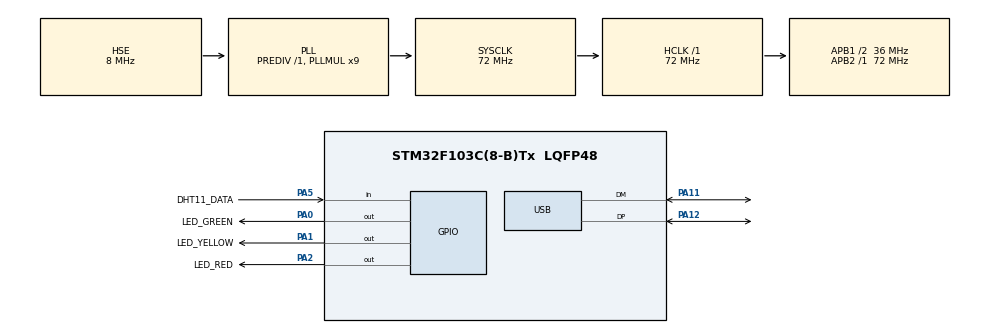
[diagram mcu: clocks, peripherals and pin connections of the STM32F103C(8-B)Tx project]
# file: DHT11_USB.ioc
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Mcu.Family=STM32F1
Mcu.Name=STM32F103C(8-B)Tx
Mcu.Package=LQFP48
NVIC.PriorityGroup=NVIC_PRIORITYGROUP_4
NVIC.USB_HP_CAN1_TX_IRQn=true\:0\:0\:false\:false\:true\:true\:true\:true
NVIC.USB_LP_CAN1_RX0_IRQn=true\:0\:0\:false\:false\:true\:false\:true\:true
PA0-WKUP.GPIO_Label=LED_GREEN
PA0-WKUP.Signal=GPIO_Output
PA1.GPIO_Label=LED_YELLOW
PA1.Signal=GPIO_Output
PA11.Mode=Device
PA11.Signal=USB_DM
PA12.Mode=Device
PA12.Signal=USB_DP
PA13.Mode=Serial_Wire
PA13.Signal=SYS_JTMS-SWDIO
PA14.Mode=Serial_Wire
PA14.Signal=SYS_JTCK-SWCLK
PA2.GPIO_Label=LED_RED
PA2.Signal=GPIO_Output
PA5.GPIO_Label=DHT11_DATA
PA5.Signal=GPIO_Input
PD0-OSC_IN.Mode=HSE-External-Oscillator
PD0-OSC_IN.Signal=RCC_OSC_IN
PD1-OSC_OUT.Mode=HSE-External-Oscillator
PD1-OSC_OUT.Signal=RCC_OSC_OUT
ProjectManager.HeapSize=0x200
ProjectManager.StackSize=0x400
ProjectManager.TargetToolchain=MDK-ARM V5.32
RCC.AHBFreq_Value=72000000
RCC.APB1CLKDivider=RCC_HCLK_DIV2
RCC.APB1Freq_Value=36000000
RCC.APB1TimFreq_Value=72000000
RCC.APB2Freq_Value=72000000
RCC.APB2TimFreq_Value=72000000
RCC.HCLKFreq_Value=72000000
RCC.PLLMUL=RCC_PLL_MUL9
RCC.SYSCLKFreq_VALUE=72000000
RCC.SYSCLKSource=RCC_SYSCLKSOURCE_PLLCLK
RCC.USBFreq_Value=48000000
RCC.USBPrescaler=RCC_USBCLKSOURCE_PLL_DIV1_5
TIM1.Prescaler=72-1
USB_DEVICE.CLASS_NAME_FS=CDC
USB_DEVICE.VirtualMode=Cdc
USB_DEVICE.VirtualModeFS=Cdc_FS
VP_TIM1_VS_ClockSourceINT.Mode=Internal
VP_USB_DEVICE_VS_USB_DEVICE_CDC_FS.Mode=CDC_FS
board=custom

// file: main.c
/* USER CODE BEGIN Header */
/**
  ******************************************************************************
  * @file           : main.c
  * @brief          : Main program body - DHT11 + USB CDC + LED control (AUTO/MANUAL)
  ******************************************************************************
  */
/* USER CODE END Header */

#include "main.h"
#include "tim.h"
#include "usb_device.h"
#include "gpio.h"

/* USER CODE BEGIN Includes */
#include "DHT11.h"
#include "usbd_cdc_if.h"
#include "mode.h"

#include <string.h>
#include <stdio.h>
/* USER CODE END Includes */

/* USER CODE BEGIN PV */
uint8_t temp = 0, humi = 0;
char msg[128];
uint32_t lastTick = 0;   // m?c th?i gian cho AUTO mode
/* USER CODE END PV */

void SystemClock_Config(void);
/* USER CODE BEGIN PFP */
void CDC_Send_String(char *s);
/* USER CODE END PFP */

/* USER CODE BEGIN 0 */
void CDC_Send_String(char *s)
{
  uint16_t len = (uint16_t)strlen(s);
  if (len == 0) return;

  while (CDC_Transmit_FS((uint8_t*)s, len) == USBD_BUSY)
  {
    HAL_Delay(1);
  }
}
/* USER CODE END 0 */

int main(void)
{
  HAL_Init();
  SystemClock_Config();

  MX_GPIO_Init();
  MX_TIM1_Init();
  MX_USB_DEVICE_Init();

  HAL_TIM_Base_Start(&htim1);

  CDC_Send_String("STM32 DHT11 USB CDC ready\r\n");

  while (1)
  {
    if (mode == MODE_AUTO)
    {
      if (HAL_GetTick() - lastTick >= 10000)
      {
        lastTick = HAL_GetTick();

        uint8_t success = 0;
        for (int i = 0; i < 3; ++i)
        {
          if (DHT11_Read(&temp, &humi) == 0)
          {
            success = 1;
            break;
          }
          HAL_Delay(100);
        }

        if (success)
        {
          HAL_GPIO_WritePin(GPIOA, GPIO_PIN_0, (humi < 40) ? GPIO_PIN_SET : GPIO_PIN_RESET);
          HAL_GPIO_WritePin(GPIOA, GPIO_PIN_1, (humi >= 40 && humi <= 70) ? GPIO_PIN_SET : GPIO_PIN_RESET);
          HAL_GPIO_WritePin(GPIOA, GPIO_PIN_2, (humi > 70) ? GPIO_PIN_SET : GPIO_PIN_RESET);

          snprintf(msg, sizeof(msg), "Temp: %d C, Humi: %d %%\r\n", temp, humi);
          CDC_Send_String(msg);
        }
        else
        {
          HAL_GPIO_WritePin(GPIOA, GPIO_PIN_0|GPIO_PIN_1|GPIO_PIN_2, GPIO_PIN_SET);
          CDC_Send_String("DHT11 Error\r\n");
        }
      }
    }
    else // MODE_MANUAL
    {
      HAL_Delay(50);
    }
  }
}

void SystemClock_Config(void)
{
  RCC_OscInitTypeDef RCC_OscInitStruct = {0};
  RCC_ClkInitTypeDef RCC_ClkInitStruct = {0};
  RCC_PeriphCLKInitTypeDef PeriphClkInit = {0};

  RCC_OscInitStruct.OscillatorType = RCC_OSCILLATORTYPE_HSE;
  RCC_OscInitStruct.HSEState = RCC_HSE_ON;
  RCC_OscInitStruct.HSEPredivValue = RCC_HSE_PREDIV_DIV1;
  RCC_OscInitStruct.HSIState = RCC_HSI_ON;
  RCC_OscInitStruct.PLL.PLLState = RCC_PLL_ON;
  RCC_OscInitStruct.PLL.PLLSource = RCC_PLLSOURCE_HSE;
  RCC_OscInitStruct.PLL.PLLMUL = RCC_PLL_MUL9;
  if (HAL_RCC_OscConfig(&RCC_OscInitStruct) != HAL_OK) Error_Handler();

  RCC_ClkInitStruct.ClockType = RCC_CLOCKTYPE_HCLK|RCC_CLOCKTYPE_SYSCLK
                              |RCC_CLOCKTYPE_PCLK1|RCC_CLOCKTYPE_PCLK2;
  RCC_ClkInitStruct.SYSCLKSource = RCC_SYSCLKSOURCE_PLLCLK;
  RCC_ClkInitStruct.AHBCLKDivider = RCC_SYSCLK_DIV1;
  RCC_ClkInitStruct.APB1CLKDivider = RCC_HCLK_DIV2;
  RCC_ClkInitStruct.APB2CLKDivider = RCC_HCLK_DIV1;
  if (HAL_RCC_ClockConfig(&RCC_ClkInitStruct, FLASH_LATENCY_2) != HAL_OK) Error_Handler();

  PeriphClkInit.PeriphClockSelection = RCC_PERIPHCLK_USB;
  PeriphClkInit.UsbClockSelection = RCC_USBCLKSOURCE_PLL_DIV1_5;
  if (HAL_RCCEx_PeriphCLKConfig(&PeriphClkInit) != HAL_OK) Error_Handler();
}

void Error_Handler(void)
{
  __disable_irq();
  while (1)
  {
    HAL_GPIO_TogglePin(GPIOA, GPIO_PIN_2);
    HAL_Delay(200);
  }
}

/* USER CODE END 4 */
